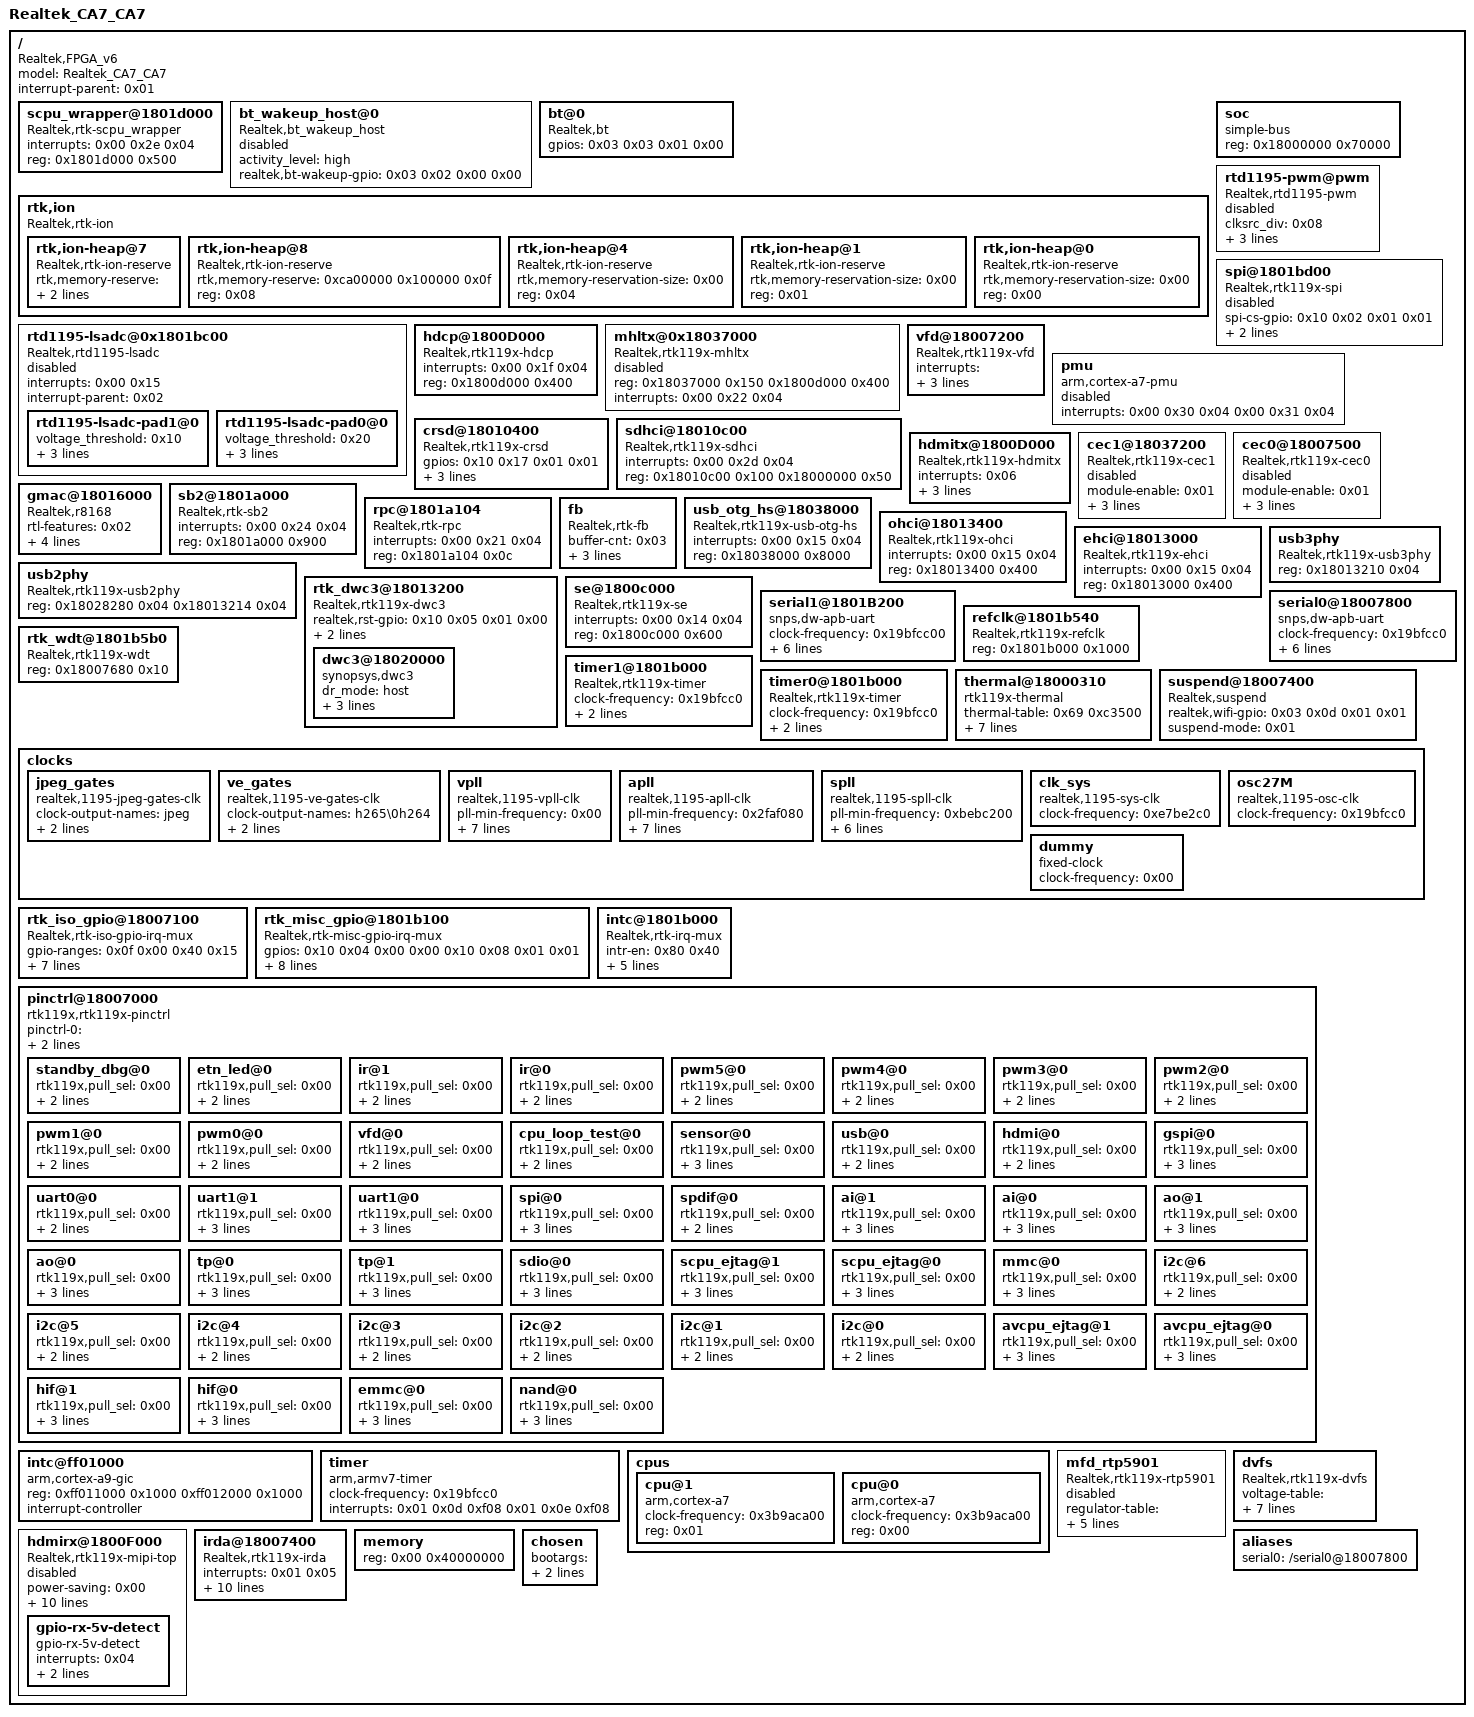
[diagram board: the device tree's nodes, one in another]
/dts-v1/;

/ {
	compatible = "Realtek,FPGA_v6\0Realtek,rtd-119x";
	model = "Realtek_CA7_CA7";
	interrupt-parent = <0x01>;
	#size-cells = <0x01>;
	#address-cells = <0x01>;

	scpu_wrapper@1801d000 {
		interrupts = <0x00 0x2e 0x04>;
		reg = <0x1801d000 0x500>;
		compatible = "Realtek,rtk-scpu_wrapper";
	};

	bt_wakeup_host@0 {
		status = "disabled";
		activity_level = "high";
		realtek,bt-wakeup-gpio = <0x03 0x02 0x00 0x00>;
		compatible = "Realtek,bt_wakeup_host";
	};

	bt@0 {
		status = "okay";
		gpios = <0x03 0x03 0x01 0x00>;
		compatible = "Realtek,bt";
	};

	rtk,ion {
		#size-cells = <0x00>;
		#address-cells = <0x01>;
		compatible = "Realtek,rtk-ion";

		rtk,ion-heap@7 {
			rtk,memory-reserve = <0xcb00000 0x3500000 0x0f 0x10100000 0x7f00000 0x0f 0x1e600000 0x1a00000 0x09 0x18100000 0x1a00000 0x09>;
			reg = <0x07>;
			compatible = "Realtek,rtk-ion-reserve";
		};

		rtk,ion-heap@8 {
			rtk,memory-reserve = <0xca00000 0x100000 0x0f>;
			reg = <0x08>;
			compatible = "Realtek,rtk-ion-reserve";
		};

		rtk,ion-heap@4 {
			rtk,memory-reservation-size = <0x00>;
			reg = <0x04>;
			compatible = "Realtek,rtk-ion-reserve";
		};

		rtk,ion-heap@1 {
			rtk,memory-reservation-size = <0x00>;
			reg = <0x01>;
			compatible = "Realtek,rtk-ion-reserve";
		};

		rtk,ion-heap@0 {
			rtk,memory-reservation-size = <0x00>;
			reg = <0x00>;
			compatible = "Realtek,rtk-ion-reserve";
		};
	};

	soc {
		ranges;
		device_type = "soc";
		compatible = "simple-bus";
		reg = <0x18000000 0x70000>;
		#size-cells = <0x01>;
		#address-cells = <0x01>;
	};

	rtd1195-lsadc@0x1801bc00 {
		status = "disabled";
		interrupts = <0x00 0x15>;
		interrupt-parent = <0x02>;
		compatible = "Realtek,rtd1195-lsadc";

		rtd1195-lsadc-pad1@0 {
			voltage_threshold = <0x10>;
			sw_idx = <0x00>;
			ctrl_mode = <0x00>;
			activate = <0x01>;
		};

		rtd1195-lsadc-pad0@0 {
			voltage_threshold = <0x20>;
			sw_idx = <0x00>;
			ctrl_mode = <0x00>;
			activate = <0x01>;
		};
	};

	rtd1195-pwm@pwm {
		status = "disabled";
		clksrc_div = <0x08>;
		duty_rate = <0x50>;
		enable = <0x00>;
		pwm_idx = <0x00>;
		#pwm-cells = <0x02>;
		compatible = "Realtek,rtd1195-pwm";
	};

	spi@1801bd00 {
		status = "disabled";
		spi-cs-gpio = <0x10 0x02 0x01 0x01>;
		pinctrl-0 = <0x16>;
		pinctrl-names = "default";
		reg = <0x1801bd00 0x28>;
		compatible = "Realtek,rtk119x-spi";
	};

	hdcp@1800D000 {
		interrupts = <0x00 0x1f 0x04>;
		reg = <0x1800d000 0x400>;
		compatible = "Realtek,rtk119x-hdcp";
	};

	mhltx@0x18037000 {
		status = "disabled";
		reg = <0x18037000 0x150 0x1800d000 0x400>;
		interrupts = <0x00 0x22 0x04>;
		compatible = "Realtek,rtk119x-mhltx";
	};

	vfd@18007200 {
		interrupts = <0x01 0x0f 0x01 0x10 0x01 0x11 0x01 0x12>;
		reg = <0x18007000 0x100 0x18007200 0x100>;
		interrupt-parent = <0x02>;
		compatible = "Realtek,rtk119x-vfd";
	};

	pmu {
		status = "disabled";
		interrupts = <0x00 0x30 0x04 0x00 0x31 0x04>;
		compatible = "arm,cortex-a7-pmu";
	};

	crsd@18010400 {
		gpios = <0x10 0x17 0x01 0x01>;
		interrupts = <0x00 0x2c 0x04>;
		reg = <0x18000000 0x400 0x18010400 0x200 0x1801a000 0x80 0x18012000 0x10 0x18010c00 0x40>;
		compatible = "Realtek,rtk119x-crsd";
	};

	sdhci@18010c00 {
		interrupts = <0x00 0x2d 0x04>;
		reg = <0x18010c00 0x100 0x18000000 0x50>;
		compatible = "Realtek,rtk119x-sdhci";
	};

	hdmitx@1800D000 {
		interrupts = <0x06>;
		interrupt-parent = <0x03>;
		gpios = <0x03 0x06 0x00 0x00>;
		reg = <0x1800d000 0x400>;
		compatible = "Realtek,rtk119x-hdmitx";
	};

	cec1@18037200 {
		status = "disabled";
		module-enable = <0x01>;
		interrupts = <0x00 0x22 0x04>;
		reg = <0x18037200 0xf0 0x18007000 0xf00 0x18037500 0x10>;
		compatible = "Realtek,rtk119x-cec1";
	};

	cec0@18007500 {
		status = "disabled";
		module-enable = <0x01>;
		interrupts = <0x01 0x16>;
		reg = <0x18007500 0xe0 0x18007040 0x04>;
		interrupt-parent = <0x02>;
		compatible = "Realtek,rtk119x-cec0";
	};

	gmac@18016000 {
		status = "okay";
		rtl-features = <0x02>;
		mac-version = <0x2a>;
		rtl-config = <0x01>;
		interrupts = <0x00 0x16 0x04>;
		reg = <0x18016000 0x1000>;
		compatible = "Realtek,r8168";
	};

	sb2@1801a000 {
		status = "okay";
		interrupts = <0x00 0x24 0x04>;
		reg = <0x1801a000 0x900>;
		compatible = "Realtek,rtk-sb2";
	};

	rpc@1801a104 {
		interrupts = <0x00 0x21 0x04>;
		reg = <0x1801a104 0x0c>;
		compatible = "Realtek,rtk-rpc";
	};

	fb {
		buffer-cnt = <0x03>;
		fps = <0x3c>;
		resolution = <0x500 0x2d0>;
		reg = <0x1e800000 0x1800000>;
		compatible = "Realtek,rtk-fb";
	};

	usb_otg_hs@18038000 {
		interrupts = <0x00 0x15 0x04>;
		reg = <0x18038000 0x8000>;
		compatible = "Realtek,rtk119x-usb-otg-hs";
	};

	ohci@18013400 {
		interrupts = <0x00 0x15 0x04>;
		reg = <0x18013400 0x400>;
		compatible = "Realtek,rtk119x-ohci";
	};

	ehci@18013000 {
		interrupts = <0x00 0x15 0x04>;
		reg = <0x18013000 0x400>;
		compatible = "Realtek,rtk119x-ehci";
	};

	usb2phy {
		phandle = <0x14>;
		linux,phandle = <0x14>;
		ranges;
		#size-cells = <0x01>;
		#address-cells = <0x01>;
		reg = <0x18028280 0x04 0x18013214 0x04>;
		compatible = "Realtek,rtk119x-usb2phy";
	};

	usb3phy {
		phandle = <0x15>;
		linux,phandle = <0x15>;
		ranges;
		#size-cells = <0x01>;
		#address-cells = <0x01>;
		reg = <0x18013210 0x04>;
		compatible = "Realtek,rtk119x-usb3phy";
	};

	rtk_dwc3@18013200 {
		realtek,rst-gpio = <0x10 0x05 0x01 0x00>;
		ranges;
		#size-cells = <0x01>;
		#address-cells = <0x01>;
		interrupts = <0x00 0x15 0x04>;
		reg = <0x18013200 0x200>;
		compatible = "Realtek,rtk119x-dwc3";

		dwc3@18020000 {
			dr_mode = "host";
			usb-phy = <0x14 0x15>;
			interrupts = <0x00 0x15 0x04>;
			reg = <0x18020000 0x9000>;
			compatible = "synopsys,dwc3";
		};
	};

	se@1800c000 {
		interrupts = <0x00 0x14 0x04>;
		reg = <0x1800c000 0x600>;
		compatible = "Realtek,rtk119x-se";
	};

	serial1@1801B200 {
		clock-frequency = <0x19bfcc00>;
		reg-io-width = <0x04>;
		reg-shift = <0x02>;
		interrupts = <0x00 0x03 0x00 0x05>;
		interrupts-st-mask = <0x08>;
		reg = <0x1801b200 0x100 0x1801b00c 0x100>;
		interrupt-parent = <0x02>;
		compatible = "snps,dw-apb-uart";
	};

	serial0@18007800 {
		clock-frequency = <0x19bfcc0>;
		reg-io-width = <0x04>;
		reg-shift = <0x02>;
		interrupts = <0x01 0x02>;
		interrupts-st-mask = <0x04>;
		reg = <0x18007800 0x400 0x18007000 0x100>;
		interrupt-parent = <0x02>;
		compatible = "snps,dw-apb-uart";
	};

	refclk@1801b540 {
		reg = <0x1801b000 0x1000>;
		compatible = "Realtek,rtk119x-refclk";
	};

	rtk_wdt@1801b5b0 {
		reg = <0x18007680 0x10>;
		compatible = "Realtek,rtk119x-wdt";
	};

	timer1@1801b000 {
		clock-frequency = <0x19bfcc0>;
		interrupts = <0x00 0x12 0x04>;
		reg = <0x1801b000 0x600>;
		compatible = "Realtek,rtk119x-timer";
	};

	timer0@1801b000 {
		clock-frequency = <0x19bfcc0>;
		interrupts = <0x00 0x11 0x04>;
		reg = <0x1801b000 0x600>;
		compatible = "Realtek,rtk119x-timer";
	};

	thermal@18000310 {
		status = "okay";
		thermal-table = <0x69 0xc3500>;
		thermal-trend-urgent = <0x00>;
		thermal-trip-shutdown = <0x00>;
		thermal-polling-ms = <0x1f4>;
		thermal1-disable = <0x00>;
		thermal0-disable = <0x00>;
		reg = <0x180171c8 0x04 0x18000310 0x04 0x18000314 0x04>;
		compatible = "rtk119x-thermal";
	};

	suspend@18007400 {
		realtek,wifi-gpio = <0x03 0x0d 0x01 0x01>;
		suspend-mode = <0x01>;
		compatible = "Realtek,suspend";
	};

	clocks {
		ranges;
		#size-cells = <0x01>;
		#address-cells = <0x01>;

		jpeg_gates {
			clock-output-names = "jpeg";
			clocks = <0x13>;
			reg = <0x1800000c 0x04>;
			#clock-cells = <0x01>;
			compatible = "realtek,1195-jpeg-gates-clk";
		};

		ve_gates {
			clock-output-names = "h265\0h264";
			clocks = <0x12>;
			reg = <0x1800000c 0x04>;
			compatible = "realtek,1195-ve-gates-clk";
			#clock-cells = <0x01>;
		};

		vpll {
			phandle = <0x12>;
			linux,phandle = <0x12>;
			clock-names = "ve";
			pll-min-frequency = <0x00>;
			pll-max-frequency = <0x3b9aca00>;
			d-min = <0x00>;
			f-min = <0x00>;
			f-max = <0x00>;
			n-min = <0x00>;
			reg = <0x18000114 0x08>;
			clocks = <0x11>;
			#clock-cells = <0x00>;
			compatible = "realtek,1195-vpll-clk";
		};

		apll {
			clock-names = "acpu";
			pll-min-frequency = <0x2faf080>;
			pll-max-frequency = <0x3b9aca00>;
			d-min = <0x00>;
			d-max = <0x00>;
			f-min = <0x00>;
			n-min = <0x00>;
			reg = <0x1800010c 0x08>;
			clocks = <0x11>;
			#clock-cells = <0x00>;
			compatible = "realtek,1195-apll-clk";
		};

		spll {
			clock-names = "scpu";
			pll-min-frequency = <0xbebc200>;
			pll-max-frequency = <0xb2d05e00>;
			d-min = <0x00>;
			f-min = <0x00>;
			n-min = <0x00>;
			reg = <0x18000000 0x134>;
			clocks = <0x11>;
			#clock-cells = <0x00>;
			compatible = "realtek,1195-spll-clk";
		};

		clk_sys {
			phandle = <0x13>;
			linux,phandle = <0x13>;
			clock-frequency = <0xe7be2c0>;
			#clock-cells = <0x00>;
			compatible = "realtek,1195-sys-clk";
		};

		osc27M {
			phandle = <0x11>;
			linux,phandle = <0x11>;
			clock-frequency = <0x19bfcc0>;
			#clock-cells = <0x00>;
			compatible = "realtek,1195-osc-clk";
		};

		dummy {
			clock-frequency = <0x00>;
			#clock-cells = <0x00>;
			compatible = "fixed-clock";
		};
	};

	rtk_iso_gpio@18007100 {
		phandle = <0x03>;
		linux,phandle = <0x03>;
		gpio-ranges = <0x0f 0x00 0x40 0x15>;
		reg = <0x18007000 0x100 0x18007100 0x100>;
		interrupts = <0x01 0x13 0x01 0x14>;
		interrupt-controller;
		#interrupt-cells = <0x01>;
		interrupt-parent = <0x02>;
		Realtek,gpio_numbers = <0x15>;
		Realtek,gpio_base = <0x3c>;
		#gpio-cells = <0x03>;
		gpio-controller;
		compatible = "Realtek,rtk-iso-gpio-irq-mux";
	};

	rtk_misc_gpio@1801b100 {
		phandle = <0x10>;
		linux,phandle = <0x10>;
		gpios = <0x10 0x04 0x00 0x00 0x10 0x08 0x01 0x01>;
		gpio-ranges = <0x0f 0x00 0x00 0x3c>;
		reg = <0x1801b000 0x100 0x1801b100 0x100>;
		interrupts = <0x00 0x13 0x00 0x14>;
		interrupt-controller;
		#interrupt-cells = <0x01>;
		interrupt-parent = <0x02>;
		Realtek,gpio_numbers = <0x3c>;
		Realtek,gpio_base = <0x00>;
		#gpio-cells = <0x03>;
		gpio-controller;
		compatible = "Realtek,rtk-misc-gpio-irq-mux";
	};

	intc@1801b000 {
		phandle = <0x02>;
		linux,phandle = <0x02>;
		intr-en = <0x80 0x40>;
		intr-status = <0x0c 0x00>;
		interrupts = <0x00 0x28 0x04 0x00 0x29 0x04>;
		reg = <0x1801b000 0x100 0x18007000 0x100>;
		interrupt-controller;
		#interrupt-cells = <0x02>;
		Realtek,mux-nr = <0x02>;
		compatible = "Realtek,rtk-irq-mux";
	};

	pinctrl@18007000 {
		phandle = <0x0f>;
		linux,phandle = <0x0f>;
		pinctrl-0 = <0x04 0x05 0x06 0x07 0x08 0x09 0x0a 0x0b 0x0c 0x0d 0x0e>;
		pinctrl-names = "default";
		#gpio-range-cells = <0x03>;
		reg = <0x18000000 0x500 0x18007000 0x400>;
		compatible = "rtk119x,rtk119x-pinctrl";

		standby_dbg@0 {
			rtk119x,pull_sel = <0x00>;
			rtk119x,function = "standby_dbg";
			rtk119x,pins = "usb0\0usb1\0ir_rx";
		};

		etn_led@0 {
			rtk119x,pull_sel = <0x00>;
			rtk119x,function = "etn_led";
			rtk119x,pins = "etn_led_link\0etn_led_rxtx";
		};

		ir@1 {
			phandle = <0x05>;
			linux,phandle = <0x05>;
			rtk119x,pull_sel = <0x00>;
			rtk119x,function = "irtx";
			rtk119x,pins = "ir_tx";
		};

		ir@0 {
			phandle = <0x04>;
			linux,phandle = <0x04>;
			rtk119x,pull_sel = <0x00>;
			rtk119x,function = "irrx";
			rtk119x,pins = "ir_rx";
		};

		pwm5@0 {
			rtk119x,pull_sel = <0x00>;
			rtk119x,function = "pwm";
			rtk119x,pins = "etn_led_rxtx";
		};

		pwm4@0 {
			rtk119x,pull_sel = <0x00>;
			rtk119x,function = "pwm";
			rtk119x,pins = "etn_led_link";
		};

		pwm3@0 {
			rtk119x,pull_sel = <0x00>;
			rtk119x,function = "pwm";
			rtk119x,pins = "ur0_rx";
		};

		pwm2@0 {
			rtk119x,pull_sel = <0x00>;
			rtk119x,function = "pwm";
			rtk119x,pins = "ur0_tx";
		};

		pwm1@0 {
			rtk119x,pull_sel = <0x00>;
			rtk119x,function = "pwm";
			rtk119x,pins = "ur1_tx";
		};

		pwm0@0 {
			rtk119x,pull_sel = <0x00>;
			rtk119x,function = "pwm";
			rtk119x,pins = "ur1_rx";
		};

		vfd@0 {
			phandle = <0x0d>;
			linux,phandle = <0x0d>;
			rtk119x,pull_sel = <0x00>;
			rtk119x,function = "vfd";
			rtk119x,pins = "vfd_cs_n\0vfd_clk\0vfd_d";
		};

		cpu_loop_test@0 {
			rtk119x,pull_sel = <0x00>;
			rtk119x,function = "cpu_loop";
			rtk119x,pins = "usb_id";
		};

		sensor@0 {
			rtk119x,pull_sel = <0x00>;
			rtk119x,function = "sensor";
			rtk119x,pins = "sensor_cko_0\0sensor_cko_\0sensor_rst\0sensor_stb_0\0sensor_stb_1";
		};

		usb@0 {
			rtk119x,pull_sel = <0x00>;
			rtk119x,function = "usb";
			rtk119x,pins = "usb_id";
		};

		hdmi@0 {
			rtk119x,pull_sel = <0x00>;
			rtk119x,function = "hdmi";
			rtk119x,pins = "hdmi_hpd";
		};

		gspi@0 {
			phandle = <0x16>;
			linux,phandle = <0x16>;
			rtk119x,pull_sel = <0x00>;
			rtk119x,function = "gspi";
			rtk119x,pins = "gpio_0\0gpio_1\0gpio_2\0gpio_3\0sf_en";
		};

		uart0@0 {
			rtk119x,pull_sel = <0x00>;
			rtk119x,function = "uart0";
			rtk119x,pins = "ur0_rx\0ur0_tx";
		};

		uart1@1 {
			phandle = <0x0c>;
			linux,phandle = <0x0c>;
			rtk119x,pull_sel = <0x00>;
			rtk119x,function = "uart1_loc_iso";
			rtk119x,pins = "ur1_rx\0ur1_tx\0ur1_cts_n\0ur1_rts_n\0ur1_loc";
		};

		uart1@0 {
			rtk119x,pull_sel = <0x00>;
			rtk119x,function = "uart1_loc_misc";
			rtk119x,pins = "gpio_0\0gpio_1\0gpio_2\0gpio_3\0ur1_loc\0sf_en";
		};

		spi@0 {
			rtk119x,pull_sel = <0x00>;
			rtk119x,function = "spi";
			rtk119x,pins = "gpio_0\0gpio_1\0gpio_2\0gpio_3\0sf_en";
		};

		spdif@0 {
			rtk119x,pull_sel = <0x00>;
			rtk119x,function = "spdif";
			rtk119x,pins = "spdif";
		};

		ai@1 {
			rtk119x,pull_sel = <0x00>;
			rtk119x,function = "ai_loc_iso_usb";
			rtk119x,pins = "usb0\0usb1\0vfd_cs_n\0vfd_clk\0ai_loc";
		};

		ai@0 {
			rtk119x,pull_sel = <0x00>;
			rtk119x,function = "ai_loc_iso_ur";
			rtk119x,pins = "ur1_rx\0ur1_tx\0ur1_cts_n\0ur1_rts_n\0ai_loc";
		};

		ao@1 {
			rtk119x,pull_sel = <0x00>;
			rtk119x,function = "ao_loc_misc";
			rtk119x,pins = "gpio_4\0gpio_5\0gpio_6\0gpio_7\0ao_loc";
		};

		ao@0 {
			rtk119x,pull_sel = <0x00>;
			rtk119x,function = "ao_loc_tp";
			rtk119x,pins = "tp0_data\0tp0_clk\0tp0_valid\0tp0_sync\0ao_loc";
		};

		tp@0 {
			rtk119x,pull_sel = <0x00>;
			rtk119x,function = "tp0";
			rtk119x,pins = "tp0_data\0tp0_clk\0tp0_valid\0tp0_sync";
		};

		tp@1 {
			rtk119x,pull_sel = <0x00>;
			rtk119x,function = "tp1";
			rtk119x,pins = "tp1_data\0tp1_clk\0tp1_valid\0tp1_sync";
		};

		sdio@0 {
			phandle = <0x0b>;
			linux,phandle = <0x0b>;
			rtk119x,pull_sel = <0x00>;
			rtk119x,function = "sdio";
			rtk119x,pins = "sdio_clk\0sdio_data_0\0sdio_data_1\0sdio_data_2\0sdio_data_3\0sdio_cmd";
		};

		scpu_ejtag@1 {
			rtk119x,pull_sel = <0x00>;
			rtk119x,function = "scpu_ejtag_loc_misc";
			rtk119x,pins = "gpio_4\0gpio_5\0gpio_6\0gpio_7\0gpio_8\0ejtag_scpu_loc";
		};

		scpu_ejtag@0 {
			rtk119x,pull_sel = <0x00>;
			rtk119x,function = "scpu_ejtag_loc_cr";
			rtk119x,pins = "mmc_data_0\0mmc_data_3\0mmc_clk\0mmc_cmd\0mmc_wp\0ejtag_scpu_loc";
		};

		mmc@0 {
			phandle = <0x0e>;
			linux,phandle = <0x0e>;
			rtk119x,pull_sel = <0x00>;
			rtk119x,function = "mmc";
			rtk119x,pins = "mmc_data_0\0mmc_data_1\0mmc_data_2\0mmc_data_3\0mmc_clk\0mmc_cmd\0mmc_wp\0mmc_cd";
		};

		i2c@6 {
			phandle = <0x0a>;
			linux,phandle = <0x0a>;
			rtk119x,pull_sel = <0x00>;
			rtk119x,function = "i2c6";
			rtk119x,pins = "i2c_scl_6\0i2c_sda_6";
		};

		i2c@5 {
			phandle = <0x09>;
			linux,phandle = <0x09>;
			rtk119x,pull_sel = <0x00>;
			rtk119x,function = "i2c5";
			rtk119x,pins = "i2c_scl_5\0i2c_sda_5";
		};

		i2c@4 {
			rtk119x,pull_sel = <0x00>;
			rtk119x,function = "i2c4";
			rtk119x,pins = "i2c_scl_4\0i2c_sda_4";
		};

		i2c@3 {
			phandle = <0x08>;
			linux,phandle = <0x08>;
			rtk119x,pull_sel = <0x00>;
			rtk119x,function = "i2c3";
			rtk119x,pins = "tp1_data\0tp1_valid";
		};

		i2c@2 {
			rtk119x,pull_sel = <0x00>;
			rtk119x,function = "i2c2";
			rtk119x,pins = "tp1_clk\0tp1_sync\0vfd_d";
		};

		i2c@1 {
			phandle = <0x07>;
			linux,phandle = <0x07>;
			rtk119x,pull_sel = <0x00>;
			rtk119x,function = "i2c1";
			rtk119x,pins = "i2c_scl_1\0i2c_sda_1";
		};

		i2c@0 {
			phandle = <0x06>;
			linux,phandle = <0x06>;
			rtk119x,pull_sel = <0x00>;
			rtk119x,function = "i2c0";
			rtk119x,pins = "i2c_scl_0\0i2c_sda_0";
		};

		avcpu_ejtag@1 {
			rtk119x,pull_sel = <0x00>;
			rtk119x,function = "avcpu_ejtag_loc_iso";
			rtk119x,pins = "usb0\0usb1\0vfd_cs_n\0vfd_clk\0vfd_d\0ejtag_avcpu_loc";
		};

		avcpu_ejtag@0 {
			rtk119x,pull_sel = <0x00>;
			rtk119x,function = "avcpu_ejtag_loc_nf";
			rtk119x,pins = "nf_dd_5\0nf_dd_6\0nf_dd_7\0nf_rdy\0nf_rd_n\0ejtag_avcpu_loc";
		};

		hif@1 {
			rtk119x,pull_sel = <0x00>;
			rtk119x,function = "hif_loc_misc";
			rtk119x,pins = "gpio_0\0gpio_1\0gpio_2\0gpio_3\0hi_loc\0sf_en";
		};

		hif@0 {
			rtk119x,pull_sel = <0x00>;
			rtk119x,function = "hif_loc_nf";
			rtk119x,pins = "nf_dd_4\0nf_wr_n\0nf_ale\0nf_cle\0hi_loc";
		};

		emmc@0 {
			rtk119x,pull_sel = <0x00>;
			rtk119x,function = "emmc";
			rtk119x,pins = "nf_dd_0\0nf_dd_1\0nf_dd_2\0nf_dd_3\0nf_dd_4\0nf_dd_5\0nf_dd_6\0nf_dd_7\0nf_rdy\0nf_rd_n\0nf_cle";
		};

		nand@0 {
			rtk119x,pull_sel = <0x00>;
			rtk119x,function = "nand";
			rtk119x,pins = "nf_dd_0\0nf_dd_1\0nf_dd_2\0nf_dd_3\0nf_dd_4\0nf_dd_5\0nf_dd_6\0nf_dd_7\0nf_rdy\0nf_rd_n\0nf_wr_n\0nf_ale\0nf_cle\0nf_ce_n_0\0nf_ce_n_1\0i2c_scl_5\0i2c_sda_5";
		};
	};

	intc@ff01000 {
		phandle = <0x01>;
		linux,phandle = <0x01>;
		reg = <0xff011000 0x1000 0xff012000 0x1000>;
		interrupt-controller;
		#interrupt-cells = <0x03>;
		compatible = "arm,cortex-a9-gic";
	};

	timer {
		clock-frequency = <0x19bfcc0>;
		interrupts = <0x01 0x0d 0xf08 0x01 0x0e 0xf08>;
		compatible = "arm,armv7-timer";
	};

	cpus {
		#size-cells = <0x00>;
		#address-cells = <0x01>;

		cpu@1 {
			clock-frequency = <0x3b9aca00>;
			reg = <0x01>;
			compatible = "arm,cortex-a7";
			device_type = "cpu";
		};

		cpu@0 {
			clock-frequency = <0x3b9aca00>;
			reg = <0x00>;
			compatible = "arm,cortex-a7";
			device_type = "cpu";
		};
	};

	mfd_rtp5901 {
		status = "disable";
		regulator-table = <0x00 0x00 0x00 0x00 0x00 0x00 0x00 0x00 0x00 0x00 0x00 0x00 0x00 0x00 0x00 0x00 0x00 0x00 0x01 0xaae60 0x13d620 0x00 0x00 0x00 0x00 0x00 0x00>;
		gpio_base = <0x51>;
		interrupts = <0x0e>;
		interrupt-parent = <0x03>;
		gpios = <0x03 0x0e 0x00 0x00>;
		compatible = "Realtek,rtk119x-rtp5901";
	};

	dvfs {
		voltage-table = <0x00 0xdbba0 0xdbba0 0x01 0x100590 0x100590 0x02 0x124f80 0x1312d0 0x03 0x1312d0 0x13d620>;
		frequency-table = <0x00 0x46cd0 0x00 0x493e0 0x00 0x5f370 0x00 0x61a80 0x01 0x7a120 0x01 0x927c0 0x01 0xafc80 0x01 0xc3500 0x02 0xdbba0 0x02 0xe6d5c 0x02 0xf4240 0x02 0x10c8e0>;
		gpios = <0x03 0x0f 0x01 0x01 0x03 0x10 0x01 0x01>;
		voltage-step-ctl = <0x01>;
		rm-threshold-uV = <0xe7ef0>;
		transition_latency = <0x7a120>;
		compatible = "Realtek,rtk119x-dvfs";
	};

	hdmirx@1800F000 {
		status = "disabled";
		power-saving = <0x00>;
		mipi_camera_type = <0x02>;
		mipi_input_type = <0x01>;
		gpio-rx-hpd-ctrl = <0x03 0x05 0x01 0x00>;
		interrupts = <0x00 0x17 0x04>;
		reg = <0x1800f000 0x418 0x1800fb00 0x100 0x18037200 0xdc 0x18037300 0x14 0x1800f600 0x1c 0x18037400 0x40 0x1800f000 0x200 0x1800f200 0x60 0x1800f260 0xa0 0x1800f300 0xc0 0x1800f3c0 0x20 0x1800f3e0 0x10 0x1800d1b0 0x10 0x18037700 0x98 0x18037600 0x98 0x18004100 0x100 0x18004000 0xf0 0x1800ff00 0x28 0x1800fd00 0x50>;
		compatible = "Realtek,rtk119x-mipi-top";
		Realtek,edid-tbl0 = <0x00 0xff 0xff 0xff 0xff 0xff 0xff 0x00 0x4a 0x8b 0x54 0x4c 0x01 0x00 0x00 0x00 0x0c 0x11 0x01 0x03 0x81 0x46 0x27 0x78 0x8a 0xa5 0x8e 0xa6 0x54 0x4a 0x9c 0x26 0x12 0x45 0x46 0xad 0xce 0x00 0x81 0x40 0x01 0x01 0x01 0x01 0x01 0x01 0x01 0x01 0x01 0x01 0x01 0x01 0x01 0x01 0x01 0x1d 0x00 0x72 0x51 0xd0 0x1e 0x20 0x6e 0x28 0x55 0x00 0xb9 0x88 0x21 0x00 0x00 0x1e 0x9a 0x29 0xa0 0xd0 0x51 0x84 0x22 0x30 0x50 0x98 0x36 0x00 0xb9 0x88 0x21 0x00 0x00 0x1c 0x00 0x00 0x00 0xfd 0x00 0x32 0x4b 0x18 0x3c 0x0b 0x00 0x0a 0x20 0x20 0x20 0x20 0x20 0x20 0x00 0x00 0x00 0xfc 0x00 0x33 0x32 0x56 0x33 0x48 0x2d 0x48 0x36 0x41 0x0a 0x20 0x20 0x20 0x01 0xe3 0x02 0x03 0x21 0x71 0x4e 0x06 0x07 0x02 0x03 0x15 0x96 0x11 0x12 0x13 0x04 0x14 0x05 0x1f 0x90 0x23 0x09 0x7f 0x07 0x83 0x01 0x00 0x00 0x65 0x03 0x0c 0x00 0x10 0x00 0x8c 0x0a 0xd0 0x90 0x20 0x40 0x31 0x20 0x0c 0x40 0x55 0x00 0xb9 0x88 0x21 0x00 0x00 0x18 0x01 0x1d 0x80 0x18 0x71 0x1c 0x16 0x20 0x58 0x2c 0x25 0x00 0xb9 0x88 0x21 0x00 0x00 0x9e 0x01 0x1d 0x80 0xd0 0x72 0x1c 0x16 0x20 0x10 0x2c 0x25 0x80 0xb9 0x88 0x21 0x00 0x00 0x9e 0x01 0x1d 0x00 0xbc 0x52 0xd0 0x1e 0x20 0xb8 0x28 0x55 0x40 0xb9 0x88 0x21 0x00 0x00 0x1e 0x02 0x3a 0x80 0xd0 0x72 0x38 0x2d 0x40 0x10 0x2c 0x45 0x80 0xb9 0x88 0x21 0x00 0x00 0x1e 0x00 0x00 0x00 0x00 0x58>;
		Realtek,edid-used-mask = <0x01>;
		Realtek,ddc-max-num = <0x01>;

		gpio-rx-5v-detect {
			interrupts = <0x04>;
			interrupt-parent = <0x03>;
			gpios = <0x03 0x04 0x00 0x00>;
			compatible = "gpio-rx-5v-detect";
		};
	};

	irda@18007400 {
		interrupts = <0x01 0x05>;
		reg = <0x18007000 0x400 0x18007400 0x100>;
		interrupt-parent = <0x02>;
		compatible = "Realtek,rtk119x-irda";
		Realtek,reg-ir-dpir = <0x32>;
		Realtek,keymap-tbl = <0x18 0x74 0x5a 0x161 0x58 0x9a 0x1a 0x179 0x14 0x66 0x56 0x165 0x54 0x166 0x19 0xe8 0x57 0x9e 0x55 0xcf 0x17 0x80 0x15 0x174 0x4f 0xa8 0x4d 0x67 0x16 0xd0 0x0c 0x69 0x4c 0x160 0x0e 0x6a 0x08 0x19c 0x48 0x6c 0x09 0x197 0x4b 0x72 0x49 0x73 0x0b 0x214 0x0a 0x213 0xeeee 0x00 0xeeee 0x01 0xffff 0x110 0xffff 0x71>;
		Realtek,custcode-msk = <0xffff>;
		Realtek,scancode-msk = <0xff0000>;
		Realtek,cust-code = <0x7f80>;
		Realtek,irtx-protocol = <0x01>;
		Realtek,irrx-protocol = <0x01>;
	};

	memory {
		reg = <0x00 0x40000000>;
		device_type = "memory";
	};

	aliases {
		serial0 = "/serial0@18007800";
	};

	chosen {
		bootargs = "console=ttyS0,115200 earlyprintk loglevel=4 ";
		linux,stdout-path = "/serial0@18007800";
	};
};
